# STM32L4Q5 register map
File version: 1.6
CPU: CM4 r0p1, little endian, MPU, FPU, 4 interrupt priority bits
Registers are 32-bit, read-write, reset 0x0 unless marked. A register's access mark holds for its fields unless they carry their own. Offsets are from the block's base; [hi:lo] are bit positions; 'fields as' and 'values as' point back to an identical list.

## RTC — Real-time clock
Base 0x40002800
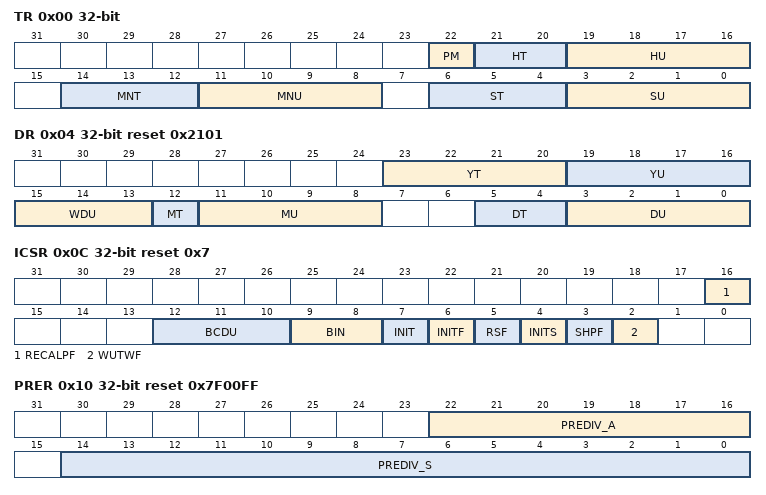
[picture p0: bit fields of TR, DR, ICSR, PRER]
0x00 TR — time register
  [22] PM — AM/PM notation
  [21:20] HT — Hour tens in BCD format
  [19:16] HU — Hour units in BCD format
  [14:12] MNT — Minute tens in BCD format
  [11:8] MNU — Minute units in BCD format
  [6:4] ST — Second tens in BCD format
  [3:0] SU — Second units in BCD format
0x04 DR reset 0x2101 — date register
  [23:20] YT — Year tens in BCD format
  [19:16] YU — Year units in BCD format
  [15:13] WDU — Week day units
  [12] MT — Month tens in BCD format
  [11:8] MU — Month units in BCD format
  [5:4] DT — Date tens in BCD format
  [3:0] DU — Date units in BCD format
0x08 SSR ro — sub second register
  [31:0] SS — Synchronous binary counter
0x0C ICSR access per field reset 0x7 — initialization control and status register
  [16] RECALPF ro — Recalibration pending Flag
  [12:10] BCDU rw — BCD update
  [9:8] BIN rw — Binary mode
  [7] INIT rw — Initialization mode
  [6] INITF ro — Initialization flag
  [5] RSF rw — Registers synchronization flag
  [4] INITS ro — Initialization status flag
  [3] SHPF ro — Shift operation pending
  [2] WUTWF ro — Wakeup timer write flag
0x10 PRER reset 0x7F00FF — prescaler register
  [22:16] PREDIV_A — Asynchronous prescaler factor
  [14:0] PREDIV_S — Synchronous prescaler factor
0x14 WUTR reset 0xFFFF — wakeup timer register
  [15:0] WUT — Wakeup auto-reload value bits
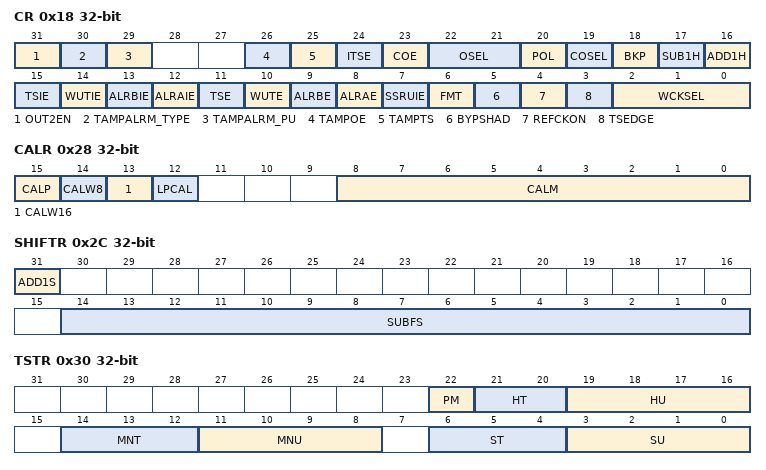
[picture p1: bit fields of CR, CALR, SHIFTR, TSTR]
0x18 CR — control register
  [31] OUT2EN — RTC_OUT2 output enable
  [30] TAMPALRM_TYPE — TAMPALRM output type
  [29] TAMPALRM_PU — TAMPALRM pull-up enable
  [26] TAMPOE — Tamper detection output enable on TAMPALRM
  [25] TAMPTS — Activate timestamp on tamper detection event
  [24] ITSE — timestamp on internal event enable
  [23] COE — Calibration output enable
  [22:21] OSEL — Output selection
  [20] POL — Output polarity
  [19] COSEL — Calibration output selection
  [18] BKP — Backup
  [17] SUB1H — Subtract 1 hour (winter time change)
  [16] ADD1H — Add 1 hour (summer time change)
  [15] TSIE — Time-stamp interrupt enable
  [14] WUTIE — Wakeup timer interrupt enable
  [13] ALRBIE — Alarm B interrupt enable
  [12] ALRAIE — Alarm A interrupt enable
  [11] TSE — Time stamp enable
  [10] WUTE — Wakeup timer enable
  [9] ALRBE — Alarm B enable
  [8] ALRAE — Alarm A enable
  [7] SSRUIE — SSR underflow interrupt enable
  [6] FMT — Hour format
  [5] BYPSHAD — Bypass the shadow registers
  [4] REFCKON — Reference clock detection enable (50 or 60 Hz)
  [3] TSEDGE — Time-stamp event active edge
  [2:0] WCKSEL — Wakeup clock selection
0x24 WPR wo — write protection register
  [7:0] KEY — Write protection key
0x28 CALR — calibration register
  [15] CALP — Increase frequency of RTC by 488.5 ppm
  [14] CALW8 — Use an 8-second calibration cycle period
  [13] CALW16 — Use a 16-second calibration cycle period
  [12] LPCAL — Calibration low-power mode
  [8:0] CALM — Calibration minus
0x2C SHIFTR wo — shift control register
  [31] ADD1S — Add one second
  [14:0] SUBFS — Subtract a fraction of a second
0x30 TSTR ro — time stamp time register
  fields as TR
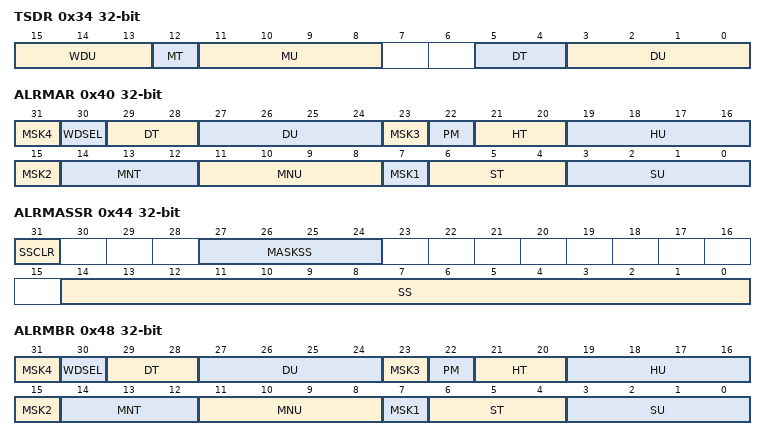
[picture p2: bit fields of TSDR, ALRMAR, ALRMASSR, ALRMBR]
0x34 TSDR ro — time stamp date register
  [15:13] WDU — Week day units
  [12] MT — Month tens in BCD format
  [11:8] MU — Month units in BCD format
  [5:4] DT — Date tens in BCD format
  [3:0] DU — Date units in BCD format
0x38 TSSSR ro — timestamp sub second register
  [31:0] SS — Sub second value
0x40 ALRMAR — alarm A register
  [31] MSK4 — Alarm A date mask
  [30] WDSEL — Week day selection
  [29:28] DT — Date tens in BCD format
  [27:24] DU — Date units or day in BCD format
  [23] MSK3 — Alarm A hours mask
  [22] PM — AM/PM notation
  [21:20] HT — Hour tens in BCD format
  [19:16] HU — Hour units in BCD format
  [15] MSK2 — Alarm A minutes mask
  [14:12] MNT — Minute tens in BCD format
  [11:8] MNU — Minute units in BCD format
  [7] MSK1 — Alarm A seconds mask
  [6:4] ST — Second tens in BCD format
  [3:0] SU — Second units in BCD format
0x44 ALRMASSR — alarm A sub second register
  [31] SSCLR — Clear synchronous counter on alarm
  [27:24] MASKSS — Mask the most-significant bits starting at this bit
  [14:0] SS — Sub seconds value
0x48 ALRMBR — alarm B register
  [31] MSK4 — Alarm B date mask
  [30] WDSEL — Week day selection
  [29:28] DT — Date tens in BCD format
  [27:24] DU — Date units or day in BCD format
  [23] MSK3 — Alarm B hours mask
  [22] PM — AM/PM notation
  [21:20] HT — Hour tens in BCD format
  [19:16] HU — Hour units in BCD format
  [15] MSK2 — Alarm B minutes mask
  [14:12] MNT — Minute tens in BCD format
  [11:8] MNU — Minute units in BCD format
  [7] MSK1 — Alarm B seconds mask
  [6:4] ST — Second tens in BCD format
  [3:0] SU — Second units in BCD format
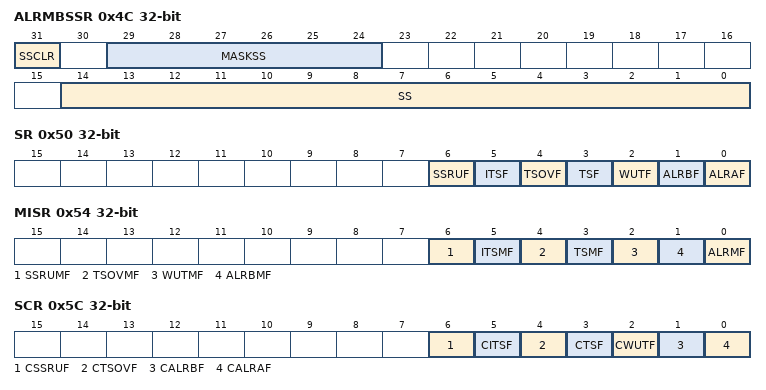
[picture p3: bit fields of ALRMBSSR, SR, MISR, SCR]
0x4C ALRMBSSR — alarm B sub second register
  [31] SSCLR — Clear synchronous counter on alarm
  [29:24] MASKSS — Mask the most-significant bits starting at this bit
  [14:0] SS — Sub seconds value
0x50 SR ro — status register
  [6] SSRUF, [5] ITSF, [4] TSOVF, [3] TSF, [2] WUTF, [1] ALRBF, [0] ALRAF
0x54 MISR ro — masked interrupt status register
  [6] SSRUMF, [5] ITSMF, [4] TSOVMF, [3] TSMF, [2] WUTMF, [1] ALRBMF, [0] ALRMF
0x5C SCR ro — status clear register
  [6] CSSRUF, [5] CITSF, [4] CTSOVF, [3] CTSF, [2] CWUTF, [1] CALRBF, [0] CALRAF
0x70 ALRABINR — alarm A binary mode register
  [31:0] SS — Synchronous counter alarm value in Binary mode
0x74 ALRBBINR — alarm B binary mode register
  [31:0] SS — Synchronous counter alarm value in Binary mode
